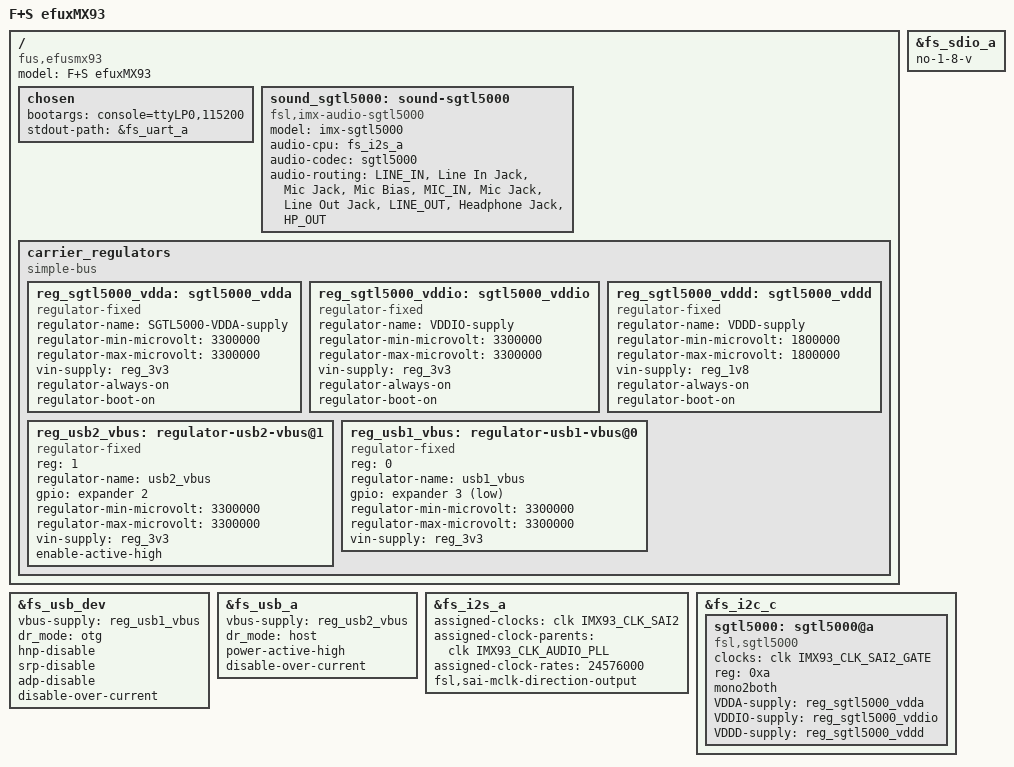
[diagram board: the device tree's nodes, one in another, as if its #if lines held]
// SPDX-License-Identifier: GPL-2.0
/*
* Copyright 2024 F&S Elektronik Systeme GmbH
*
* This program is free software; you can redistribute it and/or modify
* it under the terms of the GNU General Public License version 2 as
* published by the Free Software Foundation.
*
* This program is distributed in the hope that it will be useful,
* but WITHOUT ANY WARRANTY; without even the implied warranty of
* MERCHANTABILITY or FITNESS FOR A PARTICULAR PURPOSE.  See the
* GNU General Public License for more details.
*/

//#define SUPPORT_M33
//#define SUPPORT_RPMSG

#define CONFIG_EFUSMX93_ETH_A
#define CONFIG_EFUSMX93_ETH_B

#define CONFIG_EFUSMX93_WLAN
#define CONFIG_EFUSMX93_BLUETOOTH

#define CONFIG_EFUSMX93_UART_A
#define CONFIG_EFUSMX93_UART_B
#define CONFIG_EFUSMX93_UART_C
#define CONFIG_EFUSMX93_UART_C_RTS
#define CONFIG_EFUSMX93_UART_C_CTS
#define CONFIG_EFUSMX93_UART_D

#define CONFIG_EFUSMX93_I2C_A
#define CONFIG_EFUSMX93_I2C_B
#define CONFIG_EFUSMX93_I2C_C

#define CONFIG_EFUSMX93_SPI_A
#define CONFIG_EFUSMX93_SPI_A_B

#define CONFIG_EFUSMX93_CAN_A
#define CONFIG_EFUSMX93_CAN_B

#define CONFIG_EFUSMX93_SDIO_A
#define CONFIG_EFUSMX93_SDIO_B

#define CONFIG_EFUSMX93_USB_A
#define CONFIG_EFUSMX93_USB_DEV

#define CONFIG_EFUSMX93_PWM_BL
#define CONFIG_EFUSMX93_PWM_A

#define CONFIG_EFUSMX93_SAI
#define CONFIG_EFUSMX93_SGTL5000

#ifdef CONFIG_EFUSMX93_ETH_B
	#undef CONFIG_EFUSMX93_UART_C
	#undef CONFIG_EFUSMX93_UART_C_RTS
	#undef CONFIG_EFUSMX93_UART_C_CTS
	#undef CONFIG_EFUSMX93_UART_D
	#undef CONFIG_EFUSMX93_SAI
#endif

#ifdef	CONFIG_EFUSMX93_SAI
	#undef CONFIG_EFUSMX93_UART_C_CTS
#else
	#undef  CONFIG_EFUSMX93_SGTL5000
#endif

/dts-v1/;
#include <dt-bindings/usb/pd.h>
#include "efusmx93.dtsi"

/ {
    model = "F+S efuxMX93";
	compatible = "fus,efusmx93", "fsl,imx93";

	chosen {
		bootargs = "console=ttyLP0,115200";
		stdout-path = &fs_uart_a;
	};

#ifdef CONFIG_EFUSMX93_SGTL5000
    sound_sgtl5000: sound-sgtl5000 {
            compatible = "fsl,imx-audio-sgtl5000";
            model = "imx-sgtl5000";
            audio-cpu = <&fs_i2s_a>;
            audio-codec = <&sgtl5000>;
            audio-routing =
                "LINE_IN", "Line In Jack",
                "Mic Jack", "Mic Bias",
                "MIC_IN", "Mic Jack",
                "Line Out Jack", "LINE_OUT",
                "Headphone Jack", "HP_OUT";
        };
#endif

    carrier_regulators{
        compatible = "simple-bus";
        #address-cells = <1>;
        #size-cells = <0>;
#ifdef CONFIG_EFUSMX93_SGTL5000
		/* SGTL5000 analog voltage */
		reg_sgtl5000_vdda: sgtl5000_vdda {
			compatible = "regulator-fixed";
			regulator-name = "SGTL5000-VDDA-supply";
			regulator-min-microvolt = <3300000>;
			regulator-max-microvolt = <3300000>;
			vin-supply = <&reg_3v3>;
			regulator-always-on;
			regulator-boot-on;
		};

		/* SGTL5000 I/O voltage */
		reg_sgtl5000_vddio: sgtl5000_vddio {
			compatible = "regulator-fixed";
			regulator-name = "VDDIO-supply";
			regulator-min-microvolt = <3300000>;
			regulator-max-microvolt = <3300000>;
			vin-supply = <&reg_3v3>;
			regulator-always-on;
			regulator-boot-on;
		};

		/* SGTL5000 internal digital voltage */
		reg_sgtl5000_vddd: sgtl5000_vddd {
			compatible = "regulator-fixed";
			regulator-name = "VDDD-supply";
			regulator-min-microvolt = <1800000>;
			regulator-max-microvolt = <1800000>;
			vin-supply = <&reg_1v8>;
			regulator-always-on;
			regulator-boot-on;
		};
#endif

#ifdef CONFIG_EFUSMX93_USB_A
		reg_usb2_vbus: regulator-usb2-vbus@1 {
			compatible = "regulator-fixed";
			reg = <1>;
			regulator-name = "usb2_vbus";
			gpio = <&expander 2 GPIO_ACTIVE_HIGH>;
			regulator-min-microvolt = <3300000>;
			regulator-max-microvolt = <3300000>;
			vin-supply = <&reg_3v3>;
			enable-active-high;
		};
#endif

#ifdef CONFIG_EFUSMX93_USB_DEV
		reg_usb1_vbus: regulator-usb1-vbus@0 {
			compatible = "regulator-fixed";
			reg = <0>;
			regulator-name = "usb1_vbus";
			gpio = <&expander 3 GPIO_ACTIVE_LOW>;
			regulator-min-microvolt = <3300000>;
			regulator-max-microvolt = <3300000>;
			vin-supply = <&reg_3v3>;
		};
#endif
	};
};

#ifdef CONFIG_EFUSMX93_SDIO_A
&fs_sdio_a {
	/* Bug on SINTF. Remove if fixed */
	no-1-8-v;
};
#endif

#ifdef CONFIG_EFUSMX93_USB_DEV
&fs_usb_dev {
	vbus-supply = <&reg_usb1_vbus>;
	dr_mode = "otg";
	hnp-disable;
	srp-disable;
	adp-disable;
	disable-over-current;
};
#endif

#ifdef CONFIG_EFUSMX93_USB_A
&fs_usb_a {
	vbus-supply = <&reg_usb2_vbus>;
	dr_mode = "host";
	power-active-high;
	disable-over-current;
};
#endif

#ifdef CONFIG_EFUSMX93_SGTL5000
&fs_i2s_a {
	assigned-clocks = <&clk IMX93_CLK_SAI2>;
	assigned-clock-parents = <&clk IMX93_CLK_AUDIO_PLL>;
	assigned-clock-rates = <24576000>;
	fsl,sai-mclk-direction-output;
	status = "okay";
};

&fs_i2c_c {
	sgtl5000: sgtl5000@a {
		#sound-dai-cells = <0>;
		compatible = "fsl,sgtl5000";
		clocks = <&clk IMX93_CLK_SAI2_GATE>;
		reg = <0xa>;
		mono2both;
		VDDA-supply = <&reg_sgtl5000_vdda>;
		VDDIO-supply = <&reg_sgtl5000_vddio>;
		VDDD-supply = <&reg_sgtl5000_vddd>;
		status = "okay";
	};
};
#endif
